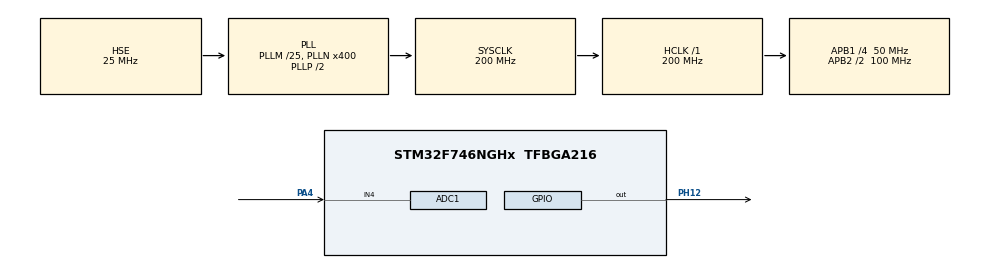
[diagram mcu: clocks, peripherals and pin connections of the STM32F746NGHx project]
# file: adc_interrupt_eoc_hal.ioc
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ADC1.Channel-0\#ChannelRegularConversion=ADC_CHANNEL_4
ADC1.ContinuousConvMode=ENABLE
ADC1.NbrOfConversionFlag=1
ADC1.Rank-0\#ChannelRegularConversion=1
ADC1.SamplingTime-0\#ChannelRegularConversion=ADC_SAMPLETIME_15CYCLES
ADC1.master=1
Mcu.Family=STM32F7
Mcu.Name=STM32F746NGHx
Mcu.Package=TFBGA216
NVIC.ADC_IRQn=true\:0\:0\:false\:false\:true\:true\:true\:true
NVIC.PriorityGroup=NVIC_PRIORITYGROUP_4
PA4.Signal=ADCx_IN4
PH0/OSC_IN.Mode=HSE-External-Oscillator
PH0/OSC_IN.Signal=RCC_OSC_IN
PH1/OSC_OUT.Mode=HSE-External-Oscillator
PH1/OSC_OUT.Signal=RCC_OSC_OUT
PH12.Signal=GPIO_Output
ProjectManager.HeapSize=0x200
ProjectManager.StackSize=0x400
ProjectManager.TargetToolchain=STM32CubeIDE
RCC.AHBFreq_Value=200000000
RCC.APB1CLKDivider=RCC_HCLK_DIV4
RCC.APB1Freq_Value=50000000
RCC.APB1TimFreq_Value=100000000
RCC.APB2CLKDivider=RCC_HCLK_DIV2
RCC.APB2Freq_Value=100000000
RCC.APB2TimFreq_Value=200000000
RCC.CortexFreq_Value=200000000
RCC.HCLKFreq_Value=200000000
RCC.HSE_VALUE=25000000
RCC.HSI_VALUE=16000000
RCC.LSE_VALUE=32768
RCC.PLL48CLockSelection=RCC_CLK48SOURCE_PLLSAIP
RCC.PLLI2SN=100
RCC.PLLM=25
RCC.PLLN=400
RCC.PLLQ=9
RCC.PLLSAIN=384
RCC.PLLSAIP=RCC_PLLSAIP_DIV8
RCC.PLLSAIR=5
RCC.PLLSAIRDiv=RCC_PLLSAIDIVR_8
RCC.PLLSourceVirtual=RCC_PLLSOURCE_HSE
RCC.SDMMCClockSelection=RCC_SDMMC1CLKSOURCE_CLK48
RCC.SYSCLKFreq_VALUE=200000000
RCC.SYSCLKSource=RCC_SYSCLKSOURCE_PLLCLK
RCC.USBFreq_Value=48000000
RCC.VCOOutputFreq_Value=400000000
SH.ADCx_IN4.0=ADC1_IN4,IN4
board=STM32F746G-DISCO

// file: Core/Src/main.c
/* USER CODE BEGIN Header */
/**
  ******************************************************************************
  * @file           : main.c
  * @brief          : Main program body
  ******************************************************************************
  * @attention
  *
  * Copyright (c) 2025 STMicroelectronics.
  * All rights reserved.
  *
  * This software is licensed under terms that can be found in the LICENSE file
  * in the root directory of this software component.
  * If no LICENSE file comes with this software, it is provided AS-IS.
  *
  ******************************************************************************
  */
/* USER CODE END Header */
#include "main.h"

ADC_HandleTypeDef hadc1;

/* USER CODE BEGIN PV */
//char txbuff[25];
uint32_t adc_result;
char adc_valid;
/* USER CODE END PV */

void SystemClock_Config(void);
static void MX_GPIO_Init(void);
static void MX_ADC1_Init(void);

int main(void)
{

  /* MCU Configuration--------------------------------------------------------*/

  /* Reset of all peripherals, Initializes the Flash interface and the Systick. */
  HAL_Init();

  /* Configure the system clock */
  SystemClock_Config();

  /* Initialize all configured peripherals */
  MX_GPIO_Init();
  MX_ADC1_Init();
  /* USER CODE BEGIN 2 */
  HAL_ADC_Start_IT(&hadc1);
  HAL_Delay(500);
 // HAL_ADCEx_Calibration_Start(&hadc1, ADC_SINGLE_ENDED);
  /* USER CODE END 2 */

  /* Infinite loop */
  /* USER CODE BEGIN WHILE */
  while (1)
  {
    /* USER CODE BEGIN 3 */

	  if(adc_valid == 1)
	  	  	  {
	  	  		  for(int i=0; i<5; i++)
	  	  		  {
	  	  			  HAL_GPIO_WritePin(GPIOH, GPIO_PIN_12, GPIO_PIN_SET);
	  	  			  HAL_Delay(1000);
	  	  			  HAL_GPIO_WritePin(GPIOH, GPIO_PIN_12, GPIO_PIN_RESET);
	  	  			  HAL_Delay(1000);
	  	  		  }
	  	  	  }

	 /* USER CODE END WHILE */
  }
  /* USER CODE END 3 */
}

void SystemClock_Config(void)
{
  RCC_OscInitTypeDef RCC_OscInitStruct = {0};
  RCC_ClkInitTypeDef RCC_ClkInitStruct = {0};

  /** Configure the main internal regulator output voltage
  */
  __HAL_RCC_PWR_CLK_ENABLE();
  __HAL_PWR_VOLTAGESCALING_CONFIG(PWR_REGULATOR_VOLTAGE_SCALE1);

  /** Initializes the RCC Oscillators according to the specified parameters
  * in the RCC_OscInitTypeDef structure.
  */
  RCC_OscInitStruct.OscillatorType = RCC_OSCILLATORTYPE_HSE;
  RCC_OscInitStruct.HSEState = RCC_HSE_ON;
  RCC_OscInitStruct.PLL.PLLState = RCC_PLL_ON;
  RCC_OscInitStruct.PLL.PLLSource = RCC_PLLSOURCE_HSE;
  RCC_OscInitStruct.PLL.PLLM = 25;
  RCC_OscInitStruct.PLL.PLLN = 400;
  RCC_OscInitStruct.PLL.PLLP = RCC_PLLP_DIV2;
  RCC_OscInitStruct.PLL.PLLQ = 9;
  if (HAL_RCC_OscConfig(&RCC_OscInitStruct) != HAL_OK)
  {
    Error_Handler();
  }

  /** Activate the Over-Drive mode
  */
  if (HAL_PWREx_EnableOverDrive() != HAL_OK)
  {
    Error_Handler();
  }

  /** Initializes the CPU, AHB and APB buses clocks
  */
  RCC_ClkInitStruct.ClockType = RCC_CLOCKTYPE_HCLK|RCC_CLOCKTYPE_SYSCLK
                              |RCC_CLOCKTYPE_PCLK1|RCC_CLOCKTYPE_PCLK2;
  RCC_ClkInitStruct.SYSCLKSource = RCC_SYSCLKSOURCE_PLLCLK;
  RCC_ClkInitStruct.AHBCLKDivider = RCC_SYSCLK_DIV1;
  RCC_ClkInitStruct.APB1CLKDivider = RCC_HCLK_DIV4;
  RCC_ClkInitStruct.APB2CLKDivider = RCC_HCLK_DIV2;

  if (HAL_RCC_ClockConfig(&RCC_ClkInitStruct, FLASH_LATENCY_6) != HAL_OK)
  {
    Error_Handler();
  }
}

static void MX_ADC1_Init(void)
{

  ADC_ChannelConfTypeDef sConfig = {0};

  /** Configure the global features of the ADC (Clock, Resolution, Data Alignment and number of conversion)
  */
  hadc1.Instance = ADC1;
  hadc1.Init.ClockPrescaler = ADC_CLOCK_SYNC_PCLK_DIV4;
  hadc1.Init.Resolution = ADC_RESOLUTION_12B;
  hadc1.Init.ScanConvMode = ADC_SCAN_DISABLE;
  hadc1.Init.ContinuousConvMode = DISABLE;  //Enabled continous conversion mode
  hadc1.Init.DiscontinuousConvMode = DISABLE;
  hadc1.Init.ExternalTrigConvEdge = ADC_EXTERNALTRIGCONVEDGE_NONE;
  hadc1.Init.ExternalTrigConv = ADC_SOFTWARE_START;
  hadc1.Init.DataAlign = ADC_DATAALIGN_RIGHT;
  hadc1.Init.NbrOfConversion = 1;
  hadc1.Init.DMAContinuousRequests = DISABLE;
  hadc1.Init.EOCSelection = ADC_EOC_SINGLE_CONV;
  HAL_NVIC_SetPriority(ADC_IRQn, 0, 0);
  HAL_NVIC_EnableIRQ(ADC_IRQn);

  if (HAL_ADC_Init(&hadc1) != HAL_OK)
  {
    Error_Handler();
  }

  /** Configure for the selected ADC regular channel its corresponding rank in the sequencer and its sample time.
  */
  sConfig.Channel = ADC_CHANNEL_4;
  sConfig.Rank = ADC_REGULAR_RANK_1;
  sConfig.SamplingTime = ADC_SAMPLETIME_15CYCLES;
  if (HAL_ADC_ConfigChannel(&hadc1, &sConfig) != HAL_OK)
  {
    Error_Handler();
  }

}

static void MX_GPIO_Init(void)
{
  GPIO_InitTypeDef GPIO_InitStruct = {0};

  /* GPIO Ports Clock Enable */
  __HAL_RCC_GPIOH_CLK_ENABLE();
  __HAL_RCC_GPIOA_CLK_ENABLE();

  /*Configure GPIO pin Output Level */
  HAL_GPIO_WritePin(GPIOH, GPIO_PIN_12, GPIO_PIN_RESET);

  /*Configure GPIO pin : PH12 */
  GPIO_InitStruct.Pin = GPIO_PIN_12;
  GPIO_InitStruct.Mode = GPIO_MODE_OUTPUT_PP;
  GPIO_InitStruct.Pull = GPIO_NOPULL;
  GPIO_InitStruct.Speed = GPIO_SPEED_FREQ_LOW;
  HAL_GPIO_Init(GPIOH, &GPIO_InitStruct);

}

/* USER CODE BEGIN 4 */

void HAL_ADC_ConvCpltCallback(ADC_HandleTypeDef* hadc)
{
		adc_result = HAL_ADC_GetValue(hadc);
		HAL_GPIO_WritePin(GPIOH, GPIO_PIN_12, GPIO_PIN_SET);
		adc_valid=1;

}
/* USER CODE END 4 */

void Error_Handler(void)
{
  __disable_irq();
  while (1)
  {
  }
}
